# STM32F302 register map
File version: 1.8
CPU: CM4 r1p0, little endian, MPU, FPU, 4 interrupt priority bits
Registers are 32-bit, read-write, reset 0x0 unless marked. A register's access mark holds for its fields unless they carry their own. Offsets are from the block's base; [hi:lo] are bit positions; {n}, {i} and the like mark numbered series; <NAME> marks a mode.

## DBGMCU — Debug support
Base 0xE0042000
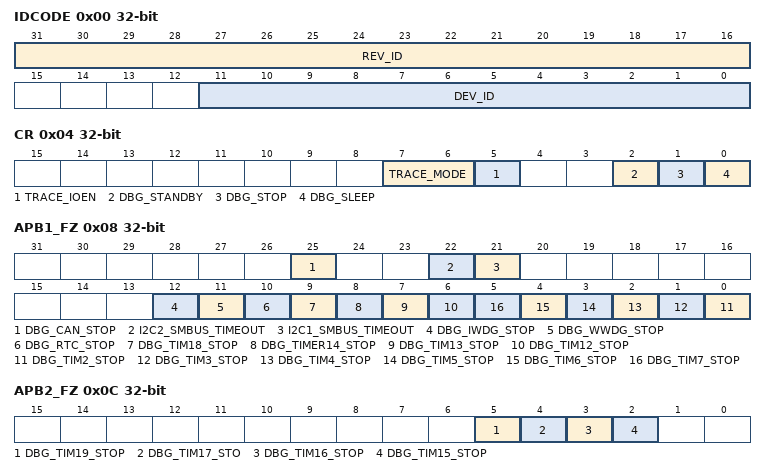
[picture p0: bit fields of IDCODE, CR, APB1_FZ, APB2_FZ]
0x00 IDCODE ro — MCU Device ID Code Register
  [31:16] REV_ID — Revision Identifier
  [11:0] DEV_ID — Device Identifier
0x04 CR — Debug MCU Configuration Register
  [7:6] TRACE_MODE — Trace pin assignment control
  [5] TRACE_IOEN — Trace pin assignment control
  [2] DBG_STANDBY — Debug Standby Mode
  [1] DBG_STOP — Debug Stop Mode
  [0] DBG_SLEEP — Debug Sleep mode
0x08 APB1_FZ — APB Low Freeze Register
  [25] DBG_CAN_STOP — Debug CAN stopped when core is halted
  [22] I2C2_SMBUS_TIMEOUT — SMBUS timeout mode stopped when Core is halted
  [21] I2C1_SMBUS_TIMEOUT — SMBUS timeout mode stopped when Core is halted
  [12] DBG_IWDG_STOP — Debug Independent Wachdog stopped when Core is halted
  [11] DBG_WWDG_STOP — Debug Window Wachdog stopped when Core is halted
  [10] DBG_RTC_STOP — Debug RTC stopped when Core is halted
  [9] DBG_TIM18_STOP — Debug Timer 18 stopped when Core is halted
  [8] DBG_TIMER14_STOP — Debug Timer 14 stopped when Core is halted
  [7] DBG_TIM13_STOP — Debug Timer 13 stopped when Core is halted
  [6] DBG_TIM12_STOP — Debug Timer 12 stopped when Core is halted
  [n-2] DBG_TIM{n}_STOP (n=2..7) — Debug Timer {n} stopped when Core is halted
0x0C APB2_FZ — APB High Freeze Register
  [5] DBG_TIM19_STOP — Debug Timer 19 stopped when Core is halted
  [4] DBG_TIM17_STO — Debug Timer 17 stopped when Core is halted
  [3] DBG_TIM16_STOP — Debug Timer 16 stopped when Core is halted
  [2] DBG_TIM15_STOP — Debug Timer 15 stopped when Core is halted

## OPAMP — Operational Amplifier
Base 0x40010000
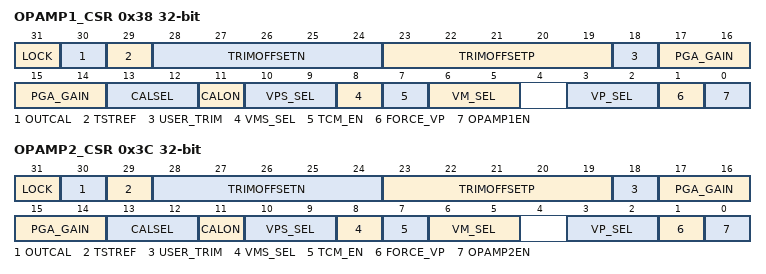
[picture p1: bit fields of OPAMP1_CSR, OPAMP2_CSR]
0x38 OPAMP1_CSR access per field — OPAMP1 control register
  [31] LOCK rw — OPAMP lock
  [30] OUTCAL ro — OPAMP ouput status flag
  [29] TSTREF rw
  [28:24] TRIMOFFSETN rw — Offset trimming value (NMOS)
  [23:19] TRIMOFFSETP rw — Offset trimming value (PMOS)
  [18] USER_TRIM rw — User trimming enable
  [17:14] PGA_GAIN rw — Gain in PGA mode
  [13:12] CALSEL rw — Calibration selection
  [11] CALON rw — Calibration mode enable
  [10:9] VPS_SEL rw — OPAMP Non inverting input secondary selection
  [8] VMS_SEL rw — OPAMP inverting input secondary selection
  [7] TCM_EN rw — Timer controlled Mux mode enable
  [6:5] VM_SEL rw — OPAMP inverting input selection
  [3:2] VP_SEL rw — OPAMP Non inverting input selection
  [1] FORCE_VP rw
  [0] OPAMP1EN rw — OPAMP1 enable
0x3C OPAMP2_CSR access per field — OPAMP2 control register
  [31] LOCK rw — OPAMP lock
    0=Unlocked (Comparator CSR bits are read-write); 1=Locked (Comparator CSR bits are read-only)
  [30] OUTCAL ro — OPAMP ouput status flag
    0=Low (Non-inverting < inverting); 1=High (Non-inverting > inverting)
  [29] TSTREF rw
    0=Output (VREFOPAMP2 is output); 1=NotOutput (VREFOPAMP2 is not output)
  [28:24] TRIMOFFSETN rw — Offset trimming value (NMOS)
  [23:19] TRIMOFFSETP rw — Offset trimming value (PMOS)
  [18] USER_TRIM rw — User trimming enable
    0=Disabled (User trimming disabled); 1=Enabled (User trimming enabled)
  [17:14] PGA_GAIN rw — Gain in PGA mode
    0=Gain2; 1=Gain4; 2=Gain8; 4=Gain16; 8=Gain2_VM0 (Gain 2, feedback connected to VM0); 9=Gain4_VM0 (Gain 4, feedback connected to VM0); 10=Gain8_VM0 (Gain 8, feedback connected to VM0); 11=Gain16_VM0 (Gain 16, feedback connected to VM0); 12=Gain2_VM1 (Gain 2, feedback connected to VM1); 13=Gain4_VM1 (Gain 4, feedback connected to VM1); 14=Gain8_VM1 (Gain 8, feedback connected to VM1); 15=Gain16_VM1 (Gain 16, feedback connected to VM1)
  [13:12] CALSEL rw — Calibration selection
    0=Percent3_3 (VREFOPAMP=3.3% VDDA); 1=Percent10 (VREFOPAMP=10% VDDA); 2=Percent50 (VREFOPAMP=50% VDDA); 3=Percent90 (VREFOPAMP=90% VDDA)
  [11] CALON rw — Calibration mode enable
    0=Disabled (Calibration mode disabled); 1=Enabled (Calibration mode enabled)
  [10:9] VPS_SEL rw — OPAMP Non inverting input secondary selection
    1=PB14 (PB14 used as OPAMP2 non-inverting input when TCM_EN=1); 2=PB0 (PB0 used as OPAMP2 non-inverting input when TCM_EN=1); 3=PA7 (PA7 used as OPAMP2 non-inverting input when TCM_EN=1)
  [8] VMS_SEL rw — OPAMP inverting input secondary selection
    0=PC5 (PC5 (VM0) used as OPAMP2 inverting input when TCM_EN=1); 1=PA5 (PA5 (VM1) used as OPAMP2 inverting input when TCM_EN=1)
  [7] TCM_EN rw — Timer controlled Mux mode enable
    0=Disabled (Timer controlled mux disabled); 1=Enabled (Timer controlled mux enabled)
  [6:5] VM_SEL rw — OPAMP inverting input selection
    0=PC5 (PC5 (VM0) used as OPAMP2 inverting input); 1=PA5 (PA5 (VM1) used as OPAMP2 inverting input); 2=PGA (Resistor feedback output (PGA mode)); 3=Follower mode
  [3:2] VP_SEL rw — OPAMP Non inverting input selection
    1=PB14 (PB14 used as OPAMP2 non-inverting input); 2=PB0 (PB0 used as OPAMP2 non-inverting input); 3=PA7 (PA7 used as OPAMP2 non-inverting input)
  [1] FORCE_VP rw
    0=Normal operating mode; 1=Calibration mode. Non-inverting input connected to calibration reference
  [0] OPAMP2EN rw — OPAMP2 enable
    0=Disabled (OPAMP2 is disabled); 1=Enabled (OPAMP2 is enabled)
